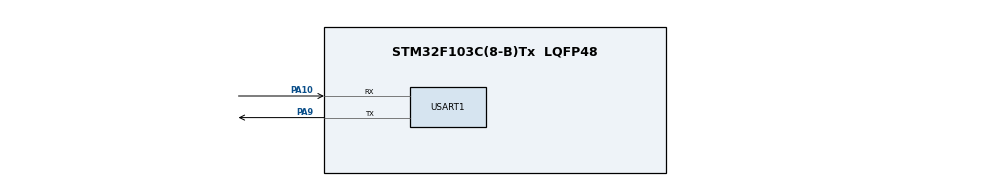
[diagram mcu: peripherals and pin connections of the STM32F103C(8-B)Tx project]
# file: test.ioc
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Mcu.Family=STM32F1
Mcu.Name=STM32F103C(8-B)Tx
Mcu.Package=LQFP48
NVIC.PriorityGroup=NVIC_PRIORITYGROUP_4
NVIC.USART1_IRQn=true\:0\:0\:false\:false\:true\:true\:true
PA10.Mode=Asynchronous
PA10.Signal=USART1_RX
PA9.Mode=Asynchronous
PA9.Signal=USART1_TX
ProjectManager.HeapSize=0x200
ProjectManager.StackSize=0x400
ProjectManager.TargetToolchain=MDK-ARM V5
RCC.APB1Freq_Value=8000000
RCC.APB2Freq_Value=8000000
USART1.VirtualMode=VM_ASYNC
VP_SYS_VS_ND.Mode=No_Debug
board=custom

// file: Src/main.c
/* USER CODE BEGIN Header */
/**
  ******************************************************************************
  * @file           : main.c
  * @brief          : Main program body
  ******************************************************************************
  * @attention
  *
  * <h2><center>&copy; Copyright (c) 2019 STMicroelectronics.
  * All rights reserved.</center></h2>
  *
  * This software component is licensed by ST under BSD 3-Clause license,
  * the "License"; You may not use this file except in compliance with the
  * License. You may obtain a copy of the License at:
  *                        opensource.org/licenses/BSD-3-Clause
  *
  ******************************************************************************
  */
/* USER CODE END Header */

#include "main.h"
#include "usart.h"
#include "gpio.h"

/* USER CODE BEGIN PV */
uint8_t aTxStartMessages[] = "\r\n******UART commucition using IT******\r\nPlease enter 10 characters:\r\n";
uint8_t aRxBuffer[20];
/* USER CODE END PV */

void SystemClock_Config(void);

int main(void)
{

  /* MCU Configuration--------------------------------------------------------*/

  /* Reset of all peripherals, Initializes the Flash interface and the Systick. */
  HAL_Init();

  /* Configure the system clock */
  SystemClock_Config();

  /* Initialize all configured peripherals */
  MX_GPIO_Init();
  MX_USART1_UART_Init();

  /* Infinite loop */
  while (1)
  {

    /* USER CODE BEGIN 3 */
	  printf("linzijei\r\n");
	//HAL_UART_Transmit_IT(&huart1 ,(uint8_t*)aTxStartMessages,sizeof(aTxStartMessages)); //sizeof()可读取目标长度
	//HAL_UART_Receive_IT(&huart1,(uint8_t*)aRxBuffer,10);
  }
  /* USER CODE END 3 */
}

void SystemClock_Config(void)
{
  RCC_OscInitTypeDef RCC_OscInitStruct = {0};
  RCC_ClkInitTypeDef RCC_ClkInitStruct = {0};

  /** Initializes the CPU, AHB and APB busses clocks
  */
  RCC_OscInitStruct.OscillatorType = RCC_OSCILLATORTYPE_HSI;
  RCC_OscInitStruct.HSIState = RCC_HSI_ON;
  RCC_OscInitStruct.HSICalibrationValue = RCC_HSICALIBRATION_DEFAULT;
  RCC_OscInitStruct.PLL.PLLState = RCC_PLL_NONE;
  if (HAL_RCC_OscConfig(&RCC_OscInitStruct) != HAL_OK)
  {
    Error_Handler();
  }
  /** Initializes the CPU, AHB and APB busses clocks
  */
  RCC_ClkInitStruct.ClockType = RCC_CLOCKTYPE_HCLK|RCC_CLOCKTYPE_SYSCLK
                              |RCC_CLOCKTYPE_PCLK1|RCC_CLOCKTYPE_PCLK2;
  RCC_ClkInitStruct.SYSCLKSource = RCC_SYSCLKSOURCE_HSI;
  RCC_ClkInitStruct.AHBCLKDivider = RCC_SYSCLK_DIV1;
  RCC_ClkInitStruct.APB1CLKDivider = RCC_HCLK_DIV1;
  RCC_ClkInitStruct.APB2CLKDivider = RCC_HCLK_DIV1;

  if (HAL_RCC_ClockConfig(&RCC_ClkInitStruct, FLASH_LATENCY_0) != HAL_OK)
  {
    Error_Handler();
  }
}

/* USER CODE BEGIN 4 */
void HAL_UART_RxCpltCallback(UART_HandleTypeDef *huart)
{
	UNUSED(huart);
	HAL_UART_Transmit(&huart1,(uint8_t*)aRxBuffer,10,0xFFFF);//(uint8_t*)aRxBuffer为字符串地址，10为字符串长度，0xFFFF为超时时间
}

/* USER CODE END 4 */

void Error_Handler(void)
{
}

/************************ (C) COPYRIGHT STMicroelectronics *****END OF FILE****/
